[part 1 of 2: packages /MICROSAR/Dem_swc/DataTypes to /MICROSAR/Dem_swc/ComponentTypes]
AUTOSAR XML (schema 00049)
package /MICROSAR/Dem_swc/DataTypes
  26 x impl type:
    Dem_EventIdType: range raw 1..65535, implementation-data-type=uint16
    Dem_RatioIdType: range raw 1..65535, implementation-data-type=uint16
    Dem_DTCStatusMaskType: range raw 0..255, implementation-data-type=uint8
    Dem_OperationCycleIdType: range raw 0..255, implementation-data-type=uint8
    Dem_DTCGroupType: range raw 0..16777215, implementation-data-type=uint32
    Dem_EventStatusType:
      compu {0=DEM_EVENT_STATUS_PASSED, 1=DEM_EVENT_STATUS_FAILED, 2=DEM_EVENT_STATUS_PREPASSED, 3=DEM_EVENT_STATUS_PREFAILED, 4=DEM_EVENT_STATUS_FDC_THRESHOLD_REACHED, 5=DEM_EVENT_STATUS_PASSED_CONDITIONS_NOT_FULFILLED, 6=DEM_EVENT_STATUS_FAILED_CONDITIONS_NOT_FULFILLED, 7=DEM_EVENT_STATUS_PREPASSED_CONDITIONS_NOT_FULFILLED, 8=DEM_EVENT_STATUS_PREFAILED_CONDITIONS_NOT_FULFILLED}
      range raw 0..255
      implementation-data-type=uint8
    Dem_InitMonitorReasonType: compu {1=DEM_INIT_MONITOR_CLEAR, 2=DEM_INIT_MONITOR_RESTART, 3=DEM_INIT_MONITOR_REENABLED, 4=DEM_INIT_MONITOR_STORAGE_REENABLED}, range raw 1..4, implementation-data-type=uint8
    Dem_DTCFormatType: compu {0=DEM_DTC_FORMAT_OBD, 1=DEM_DTC_FORMAT_UDS, 2=DEM_DTC_FORMAT_J1939}, range raw 0..2, implementation-data-type=uint8
    Dem_OperationCycleStateType: compu {0=DEM_CYCLE_STATE_START, 1=DEM_CYCLE_STATE_END}, range raw 0..1, implementation-data-type=uint8
    Dem_IndicatorStatusType: compu {0=DEM_INDICATOR_OFF, 1=DEM_INDICATOR_CONTINUOUS, 2=DEM_INDICATOR_BLINKING, 3=DEM_INDICATOR_BLINK_CONT, 4=DEM_INDICATOR_SLOW_FLASH, 5=DEM_INDICATOR_FAST_FLASH, 6=DEM_INDICATOR_ON_DEMAND, 7=DEM_INDICATOR_SHORT}, range raw 0..7, implementation-data-type=uint8
    Dem_DTCKindType: compu {1=DEM_DTC_KIND_ALL_DTCS, 2=DEM_DTC_KIND_EMISSION_REL_DTCS}, range raw 0..255, implementation-data-type=uint8
    Dem_IumprDenomCondIdType: compu {1=DEM_IUMPR_GENERAL_DENOMINATOR, 2=DEM_IUMPR_DEN_COND_COLDSTART, 3=DEM_IUMPR_DEN_COND_EVAP, 4=DEM_IUMPR_DEN_COND_500MI, 5=DEM_IUMPR_GENERAL_INDIVIDUAL_DENOMINATOR, 6=DEM_IUMPR_GENERAL_OBDCOND, 7=DEM_IUMPR_DEN_COND_INDEPENDENT}, range raw 0..255, implementation-data-type=uint8
    Dem_IumprDenomCondStatusType: compu {0=DEM_IUMPR_DEN_STATUS_NOT_REACHED, 1=DEM_IUMPR_DEN_STATUS_REACHED, 2=DEM_IUMPR_DEN_STATUS_INHIBITED}, range raw 0..255, implementation-data-type=uint8
    Dem_DebounceResetStatusType: compu {0=DEM_DEBOUNCE_STATUS_FREEZE, 1=DEM_DEBOUNCE_STATUS_RESET}, range raw 0..255, implementation-data-type=uint8
    Dem_IumprReadinessGroupType:
      compu {0=DEM_IUMPR_BOOSTPRS, 1=DEM_IUMPR_CAT1, 2=DEM_IUMPR_CAT2, 3=DEM_IUMPR_EGR, 4=DEM_IUMPR_EGSENSOR, 5=DEM_IUMPR_EVAP, 6=DEM_IUMPR_NMHCCAT, 7=DEM_IUMPR_NOXADSORB, 8=DEM_IUMPR_NOXCAT, 9=DEM_IUMPR_OXS1, 10=DEM_IUMPR_OXS2, 11=DEM_IUMPR_PMFILTER, 12=DEM_IUMPR_PRIVATE, 13=DEM_IUMPR_SAIR, 14=DEM_IUMPR_SECOXS1, 15=DEM_IUMPR_SECOXS2, 16=DEM_IUMPR_FLSYS, 17=DEM_IUMPR_AFRI1, 18=DEM_IUMPR_AFRI2, 19=DEM_IUMPR_PF1, 20=DEM_IUMPR_PF2, 255=DEM_IUMPR_ALLGROUPS}
      range raw 0..255
      implementation-data-type=uint8
    Dem_DTRControlType: compu {0=DEM_DTR_CTL_NORMAL, 1=DEM_DTR_CTL_NO_MAX, 2=DEM_DTR_CTL_NO_MIN, 3=DEM_DTR_CTL_RESET, 4=DEM_DTR_CTL_INVISIBLE}, range raw 0..255, implementation-data-type=uint8
    Dem_DebouncingStateType:
      compu {mask 1: 1=DEM_TEMPORARILY_DEFECTIVE (Bit 0: Temporarily Defective (corresponds to 0 < FDC < 127)), mask 2: 2=DEM_FINALLY_DEFECTIVE (Bit 1: Finally Defective (corresponds to FDC = 127)), mask 4: 4=DEM_TEMPORARILY_HEALED (Bit 2: Temporarily healed (corresponds to -128 < FDC < 0)), mask 8: 8=DEM_TEST_COMPLETE (Bit 3: Test complete (corresponds to FDC = -128 or FDC = 127)), mask 16: 16=DEM_DTR_UPDATE (Bit 4: DTR Update (= Test complete && Debouncing complete && enable conditions / storage conditions fulfilled))}
      range raw 0..255
      implementation-data-type=uint8
    Dem_DTCSeverityType:
      compu {mask 255: 0=DEM_SEVERITY_NO_SEVERITY (DTC_NO_SEVERITY) (No severity information available), mask 31: 1=DEM_SEVERITY_WWHOBD_CLASS_NO_CLASS (DTC_CLASS) (No class information), mask 31: 2=DEM_SEVERITY_WWHOBD_CLASS_A (DTC_CLASS) (WWH-OBD Class A), mask 31: 4=DEM_SEVERITY_WWHOBD_CLASS_B1 (DTC_CLASS) (WWH-OBD Class B1), mask 31: 8=DEM_SEVERITY_WWHOBD_CLASS_B2 (DTC_CLASS) (WWH-OBD Class B2), mask 31: 16=DEM_SEVERITY_WWHOBD_CLASS_C (DTC_CLASS) (WWH-OBD Class C), mask 224: 32=DEM_SEVERITY_MAINTENANCE_ONLY (DTC_SEVERITY) (Maintenance required), mask 224: 64=DEM_SEVERITY_CHECK_AT_NEXT_HALT (DTC_SEVERITY) (Check at next halt), mask 224: 128=DEM_SEVERITY_CHECK_IMMEDIATELY (DTC_SEVERITY) (Check immediately)}
      range raw 0..255
      implementation-data-type=uint8
    Dem_UdsStatusByteType:
      compu {mask 1: 1=DEM_UDS_STATUS_TF (bit 0: TestFailed), mask 2: 2=DEM_UDS_STATUS_TFTOC (bit 1: TestFailedThisOperationCycle), mask 4: 4=DEM_UDS_STATUS_PDTC (bit 2: PendingDTC), mask 8: 8=DEM_UDS_STATUS_CDTC (bit 3: ConfirmedDTC), mask 16: 16=DEM_UDS_STATUS_TNCSLC (bit 4: TestNotCompletedSinceLastClear), mask 32: 32=DEM_UDS_STATUS_TFSLC (bit 5: TestFailedSinceLastClear), mask 64: 64=DEM_UDS_STATUS_TNCTOC (bit 6: TestNotCompletedThisOperationCycle), mask 128: 128=DEM_UDS_STATUS_WIR (bit 7: WarningIndicatorRequested)}
      range raw 0..255
      implementation-data-type=uint8
    Dem_MonitorStatusType: compu {mask 1: 1=DEM_MONITOR_STATUS_TF (bit 0: TestFailed), mask 2: 2=DEM_MONITOR_STATUS_TNCTOC (bit 1: TestNotCompletedThisOperationCycle)}, range raw 0..255, implementation-data-type=uint8
    Dem_DTCOriginType: compu {1=DEM_DTC_ORIGIN_PRIMARY_MEMORY, 2=DEM_DTC_ORIGIN_MIRROR_MEMORY, 3=DEM_DTC_ORIGIN_PERMANENT_MEMORY, 4=DEM_DTC_ORIGIN_OBD_RELEVANT_MEMORY, 256=DEM_DTC_ORIGIN_SECONDARY_MEMORY}, range raw 1..511, implementation-data-type=uint16
    DataPrimitiveType_uint32: implementation-data-type=uint32
    DataPrimitiveType_uint16: implementation-data-type=uint16
    DataPrimitiveType_uint8: implementation-data-type=uint8
    DataArrayType_uint8_2: category=ARRAY, sw-calibration-access=READ-ONLY
      element DataArrayType_uint8_2Element: array-size=2, array-size-semantics=FIXED-SIZE, implementation-data-type=uint8
    Dem_MaxDataValueType: category=ARRAY, sw-calibration-access=READ-ONLY
      element Dem_MaxDataValueTypeElement: array-size=5, array-size-semantics=FIXED-SIZE, implementation-data-type=uint8
package /MICROSAR/Dem_swc/Interfaces
  19 x client server interface, all with is-service=true, service-kind=DIAGNOSTIC-EVENT-MANAGER:
    DemServices
      operation GetPostRunRequested: possible-error=DemServices/E_NOT_OK
        arg IsRequested: type=boolean, direction=OUT
      operation GetDTCStatusAvailabilityMask: possible-error=DemServices/E_NOT_OK
        arg ClientId: type=uint8, direction=IN
        arg DTCStatusMask: type=uint8, direction=OUT
      error E_NOT_OK: error-code=1
    DemSc
      operation GetCurrentOdometer: possible-error=DemSc/E_NOT_OK
        arg Odometer: type=uint32, direction=OUT
      operation GetExternalTesterStatus: possible-error=DemSc/E_NOT_OK
        arg TesterPresent: type=boolean, direction=OUT
      error E_NOT_OK: error-code=1
    ClearDTC
      operation ClearDTC: possible-error=[ClearDTC/E_NOT_OK, DEM_CLEAR_FAILED, ClearDTC/DEM_PENDING, DEM_CLEAR_BUSY, DEM_CLEAR_MEMORY_ERROR, ClearDTC/DEM_WRONG_DTC, ClearDTC/DEM_WRONG_DTCORIGIN]
      operation SelectDTC: possible-error=[ClearDTC/E_OK, ClearDTC/E_NOT_OK]
        arg DTC: type=uint32, direction=IN
        arg DTCFormat: type=Dem_DTCFormatType, direction=IN
        arg DTCOrigin: type=Dem_DTCOriginType, direction=IN
      8 x error:
        E_OK: error-code=0
        E_NOT_OK: error-code=1
        DEM_CLEAR_FAILED: error-code=7
        DEM_PENDING: error-code=4
        DEM_CLEAR_BUSY: error-code=5
        DEM_CLEAR_MEMORY_ERROR: error-code=6
        DEM_WRONG_DTC: error-code=8
        DEM_WRONG_DTCORIGIN: error-code=9
    EnableCondition
      operation SetEnableCondition: possible-error=EnableCondition/E_NOT_OK
        arg ConditionFulfilled: type=boolean, direction=IN
      error E_NOT_OK: error-code=1
    IndicatorStatus
      operation GetIndicatorStatus: possible-error=IndicatorStatus/E_NOT_OK
        arg IndicatorStatus: type=Dem_IndicatorStatusType, direction=OUT
      error E_NOT_OK: error-code=1
    EvMemOverflowIndication
      operation GetEventMemoryOverflow: possible-error=EvMemOverflowIndication/E_NOT_OK
        arg OverflowIndication: type=boolean, direction=OUT
      operation GetNumberOfEventMemoryEntries: possible-error=EvMemOverflowIndication/E_NOT_OK
        arg NumberOfEventMemoryEntries: type=uint8, direction=OUT
      error E_NOT_OK: error-code=1
    GeneralDiagnosticInfo
      11 x operation:
        GetEventUdsStatus: possible-error=GeneralDiagnosticInfo/E_NOT_OK
          arg EventId: type=Dem_EventIdType, direction=IN
          arg UDSStatusByte: type=Dem_UdsStatusByteType, direction=OUT
        GetEventStatus: possible-error=GeneralDiagnosticInfo/E_NOT_OK
          arg EventId: type=Dem_EventIdType, direction=IN
          arg UDSStatusByte: type=Dem_UdsStatusByteType, direction=OUT
        GetEventFailed: possible-error=GeneralDiagnosticInfo/E_NOT_OK
          arg EventId: type=Dem_EventIdType, direction=IN
          arg EventFailed: type=boolean, direction=OUT
        GetEventTested: possible-error=GeneralDiagnosticInfo/E_NOT_OK
          arg EventId: type=Dem_EventIdType, direction=IN
          arg EventTested: type=boolean, direction=OUT
        GetDTCOfEvent: possible-error=[GeneralDiagnosticInfo/E_NOT_OK, GeneralDiagnosticInfo/DEM_E_NO_DTC_AVAILABLE]
          arg EventId: type=Dem_EventIdType, direction=IN
          arg DTCFormat: type=Dem_DTCFormatType, direction=IN
          arg DTCOfEvent: type=uint32, direction=OUT
        GetFaultDetectionCounter: possible-error=[GeneralDiagnosticInfo/E_NOT_OK, GeneralDiagnosticInfo/DEM_E_NO_FDC_AVAILABLE]
          arg EventId: type=Dem_EventIdType, direction=IN
          arg FaultDetectionCounter: type=sint8, direction=OUT
        GetEventFreezeFrameDataEx: possible-error=[GeneralDiagnosticInfo/E_NOT_OK, GeneralDiagnosticInfo/DEM_BUFFER_TOO_SMALL, GeneralDiagnosticInfo/DEM_NO_SUCH_ELEMENT]
          5 x arg:
            EventId: type=Dem_EventIdType, direction=IN
            RecordNumber: type=uint8, direction=IN
            DataId: type=uint16, direction=IN
            DestBuffer: type=Dem_MaxDataValueType, direction=OUT
            BufSize: type=uint16, direction=INOUT
        GetEventExtendedDataRecordEx: possible-error=[GeneralDiagnosticInfo/E_NOT_OK, GeneralDiagnosticInfo/DEM_BUFFER_TOO_SMALL, GeneralDiagnosticInfo/DEM_NO_SUCH_ELEMENT]
          4 x arg:
            EventId: type=Dem_EventIdType, direction=IN
            RecordNumber: type=uint8, direction=IN
            DestBuffer: type=Dem_MaxDataValueType, direction=OUT
            BufSize: type=uint16, direction=INOUT
        GetEventEnableCondition: possible-error=GeneralDiagnosticInfo/E_NOT_OK
          arg EventId: type=Dem_EventIdType, direction=IN
          arg ConditionFullfilled: type=boolean, direction=OUT
        GetDebouncingOfEvent: possible-error=GeneralDiagnosticInfo/E_NOT_OK
          arg EventId: type=Dem_EventIdType, direction=IN
          arg DebouncingState: type=Dem_DebouncingStateType, direction=OUT
        GetMonitorStatus: possible-error=GeneralDiagnosticInfo/E_NOT_OK
          arg EventId: type=Dem_EventIdType, direction=IN
          arg MonitorStatus: type=Dem_MonitorStatusType, direction=OUT
      5 x error:
        E_NOT_OK: error-code=1
        DEM_E_NO_DTC_AVAILABLE: error-code=10
        DEM_E_NO_FDC_AVAILABLE: error-code=14
        DEM_BUFFER_TOO_SMALL: error-code=21
        DEM_NO_SUCH_ELEMENT: error-code=48
    OperationCycle
      operation GetOperationCycleState: possible-error=[OperationCycle/E_OK, OperationCycle/E_NOT_OK]
        arg CycleState: type=Dem_OperationCycleStateType, direction=OUT
      operation SetOperationCycleState: possible-error=[OperationCycle/E_OK, OperationCycle/E_NOT_OK]
        arg CycleState: type=Dem_OperationCycleStateType, direction=IN
      error E_OK: error-code=0
      error E_NOT_OK: error-code=1
    CallbackDTCStatusChange
      operation DTCStatusChanged: possible-error=CallbackDTCStatusChange/E_NOT_OK
        arg DTC: type=uint32, direction=IN
        arg DTCStatusOld: type=Dem_UdsStatusByteType, direction=IN
        arg DTCStatusNew: type=Dem_UdsStatusByteType, direction=IN
      error E_NOT_OK: error-code=1
    CSDataServices_Data_DID_0x133_Current_Operating_Time
      operation ReadData: possible-error=CSDataServices_Data_DID_0x133_Current_Operating_Time/E_NOT_OK
        arg Data: type=DataPrimitiveType_uint32, direction=OUT
      error E_NOT_OK: error-code=1
    CSDataServices_Data_DID_0x10a_Vehicle_Odometer_in_Low_Resolution
      operation ReadData: possible-error=CSDataServices_Data_DID_0x10a_Vehicle_Odometer_in_Low_Resolution/E_NOT_OK
        arg Data: type=DataPrimitiveType_uint16, direction=OUT
      error E_NOT_OK: error-code=1
    CSDataServices_Data_DID_0x18b_SecOcDataID
      operation ReadData: possible-error=CSDataServices_Data_DID_0x18b_SecOcDataID/E_NOT_OK
        arg Data: type=DataArrayType_uint8_2, direction=OUT
      error E_NOT_OK: error-code=1
    CSDataServices_Data_DID_0x133_Operating_Time_Status
      operation ReadData: possible-error=CSDataServices_Data_DID_0x133_Operating_Time_Status/E_NOT_OK
        arg Data: type=DataPrimitiveType_uint8, direction=OUT
      error E_NOT_OK: error-code=1
    DiagnosticInfo
      11 x operation:
        GetEventUdsStatus: possible-error=DiagnosticInfo/E_NOT_OK
          arg UDSStatusByte: type=Dem_UdsStatusByteType, direction=OUT
        GetEventStatus: possible-error=DiagnosticInfo/E_NOT_OK
          arg UDSStatusByte: type=Dem_UdsStatusByteType, direction=OUT
        GetEventFailed: possible-error=DiagnosticInfo/E_NOT_OK
          arg EventFailed: type=boolean, direction=OUT
        GetEventTested: possible-error=DiagnosticInfo/E_NOT_OK
          arg EventTested: type=boolean, direction=OUT
        GetDTCOfEvent: possible-error=[DiagnosticInfo/E_NOT_OK, DiagnosticInfo/DEM_E_NO_DTC_AVAILABLE]
          arg DTCFormat: type=Dem_DTCFormatType, direction=IN
          arg DTCOfEvent: type=uint32, direction=OUT
        GetFaultDetectionCounter: possible-error=[DiagnosticInfo/E_NOT_OK, DiagnosticInfo/DEM_E_NO_FDC_AVAILABLE]
          arg FaultDetectionCounter: type=sint8, direction=OUT
        GetEventFreezeFrameDataEx: possible-error=[DiagnosticInfo/E_NOT_OK, DiagnosticInfo/DEM_BUFFER_TOO_SMALL, DiagnosticInfo/DEM_NO_SUCH_ELEMENT]
          4 x arg:
            RecordNumber: type=uint8, direction=IN
            DataId: type=uint16, direction=IN
            DestBuffer: type=Dem_MaxDataValueType, direction=OUT
            BufSize: type=uint16, direction=INOUT
        GetEventExtendedDataRecordEx: possible-error=[DiagnosticInfo/E_NOT_OK, DiagnosticInfo/DEM_BUFFER_TOO_SMALL, DiagnosticInfo/DEM_NO_SUCH_ELEMENT]
          arg RecordNumber: type=uint8, direction=IN
          arg DestBuffer: type=Dem_MaxDataValueType, direction=OUT
          arg BufSize: type=uint16, direction=INOUT
        GetEventEnableCondition: possible-error=DiagnosticInfo/E_NOT_OK
          arg ConditionFullfilled: type=boolean, direction=OUT
        GetDebouncingOfEvent: possible-error=DiagnosticInfo/E_NOT_OK
          arg DebouncingState: type=Dem_DebouncingStateType, direction=OUT
        GetMonitorStatus: possible-error=DiagnosticInfo/E_NOT_OK
          arg MonitorStatus: type=Dem_MonitorStatusType, direction=OUT
      5 x error:
        E_NOT_OK: error-code=1
        DEM_E_NO_DTC_AVAILABLE: error-code=10
        DEM_E_NO_FDC_AVAILABLE: error-code=14
        DEM_BUFFER_TOO_SMALL: error-code=21
        DEM_NO_SUCH_ELEMENT: error-code=48
    DiagnosticMonitor
      11 x operation:
        SetEventStatus: possible-error=DiagnosticMonitor/E_NOT_OK
          arg EventStatus: type=Dem_EventStatusType, direction=IN
        ResetEventStatus: possible-error=DiagnosticMonitor/E_NOT_OK
        ResetEventDebounceStatus: possible-error=DiagnosticMonitor/E_NOT_OK
          arg DebounceResetStatus: type=Dem_DebounceResetStatusType, direction=IN
        GetEventUdsStatus: possible-error=DiagnosticMonitor/E_NOT_OK
          arg UDSStatusByte: type=Dem_UdsStatusByteType, direction=OUT
        GetEventStatus: possible-error=DiagnosticMonitor/E_NOT_OK
          arg UDSStatusByte: type=Dem_UdsStatusByteType, direction=OUT
        GetEventFailed: possible-error=DiagnosticMonitor/E_NOT_OK
          arg EventFailed: type=boolean, direction=OUT
        GetEventTested: possible-error=DiagnosticMonitor/E_NOT_OK
          arg EventTested: type=boolean, direction=OUT
        GetDTCOfEvent: possible-error=[DiagnosticMonitor/E_NOT_OK, DiagnosticMonitor/DEM_E_NO_DTC_AVAILABLE]
          arg DTCFormat: type=Dem_DTCFormatType, direction=IN
          arg DTCOfEvent: type=uint32, direction=OUT
        GetFaultDetectionCounter: possible-error=[DiagnosticMonitor/E_NOT_OK, DiagnosticMonitor/DEM_E_NO_FDC_AVAILABLE]
          arg FaultDetectionCounter: type=sint8, direction=OUT
        GetEventFreezeFrameDataEx: possible-error=[DiagnosticMonitor/E_NOT_OK, DiagnosticMonitor/DEM_BUFFER_TOO_SMALL, DiagnosticMonitor/DEM_NO_SUCH_ELEMENT]
          4 x arg:
            RecordNumber: type=uint8, direction=IN
            DataId: type=uint16, direction=IN
            DestBuffer: type=Dem_MaxDataValueType, direction=OUT
            BufSize: type=uint16, direction=INOUT
        GetEventExtendedDataRecordEx: possible-error=[DiagnosticMonitor/E_NOT_OK, DiagnosticMonitor/DEM_BUFFER_TOO_SMALL, DiagnosticMonitor/DEM_NO_SUCH_ELEMENT]
          arg RecordNumber: type=uint8, direction=IN
          arg DestBuffer: type=Dem_MaxDataValueType, direction=OUT
          arg BufSize: type=uint16, direction=INOUT
      5 x error:
        E_NOT_OK: error-code=1
        DEM_E_NO_DTC_AVAILABLE: error-code=10
        DEM_E_NO_FDC_AVAILABLE: error-code=14
        DEM_BUFFER_TOO_SMALL: error-code=21
        DEM_NO_SUCH_ELEMENT: error-code=48
    CallbackInitMonitorForEvent
      operation InitMonitorForEvent: possible-error=CallbackInitMonitorForEvent/E_NOT_OK
        arg InitMonitorReason: type=Dem_InitMonitorReasonType, direction=IN
      error E_NOT_OK: error-code=1
    DTCSuppression
      operation SetDTCSuppression: possible-error=[DTCSuppression/E_NOT_OK, DTCSuppression/DEM_WRONG_DTC, DTCSuppression/DEM_WRONG_DTCORIGIN, DTCSuppression/DEM_PENDING]
        arg SuppressionStatus: type=boolean, direction=IN
      operation GetDTCSuppression: possible-error=[DTCSuppression/E_NOT_OK, DTCSuppression/DEM_WRONG_DTC, DTCSuppression/DEM_WRONG_DTCORIGIN, DTCSuppression/DEM_PENDING]
        arg SuppressionStatus: type=boolean, direction=OUT
      4 x error:
        E_NOT_OK: error-code=1
        DEM_WRONG_DTC: error-code=8
        DEM_WRONG_DTCORIGIN: error-code=9
        DEM_PENDING: error-code=4
    StorageCondition
      operation SetStorageCondition: possible-error=StorageCondition/E_NOT_OK
        arg ConditionFulfilled: type=boolean, direction=IN
      error E_NOT_OK: error-code=1
    CSDataServices_Data_DID_0xfd05_Root_Causes
      operation ReadData: possible-error=CSDataServices_Data_DID_0xfd05_Root_Causes/E_NOT_OK
        arg Data: type=DataPrimitiveType_uint8, direction=OUT
      error E_NOT_OK: error-code=1
package /MICROSAR/Dem_swc/ComponentTypes
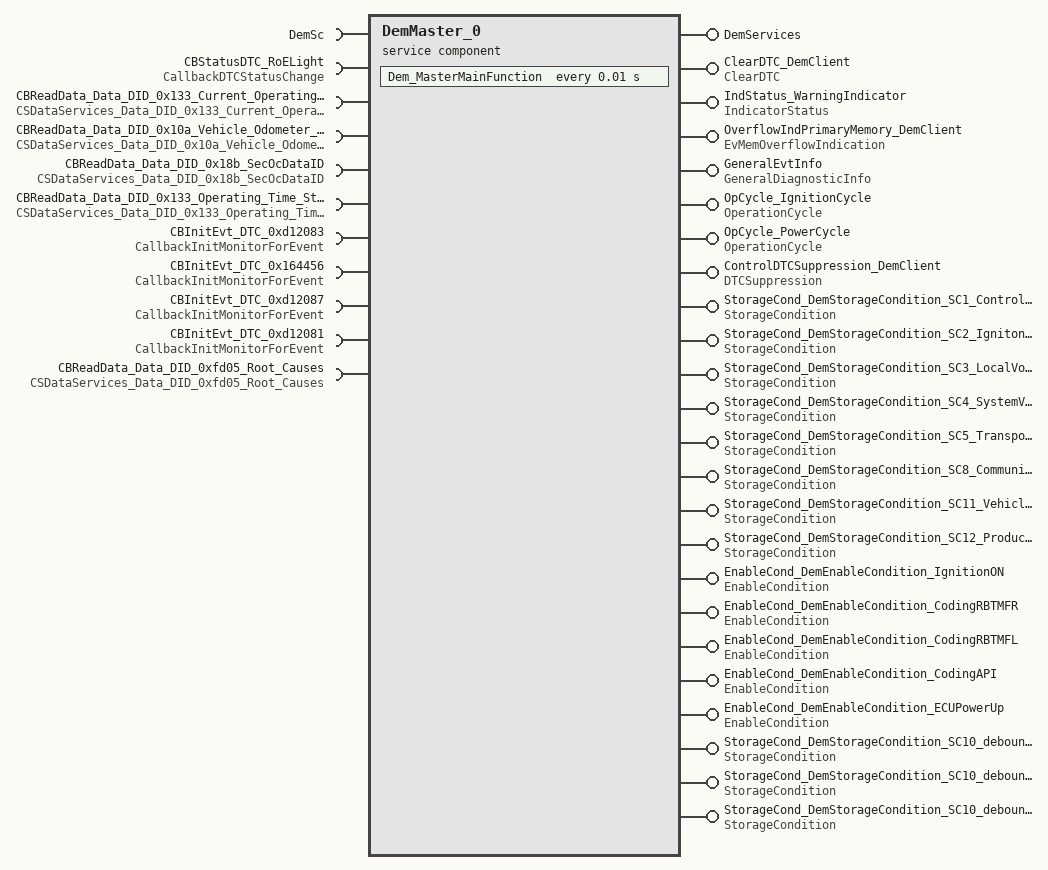
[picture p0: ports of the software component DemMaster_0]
  service sw component type DemMaster_0: category=SERVICE_COMPONENT
    provide port DemServices: provided-interface=DemServices
    require port DemSc: required-interface=DemSc
    6 x provide port:
      ClearDTC_DemClient: provided-interface=ClearDTC
      IndStatus_WarningIndicator: provided-interface=IndicatorStatus
      OverflowIndPrimaryMemory_DemClient: provided-interface=EvMemOverflowIndication
      GeneralEvtInfo: provided-interface=GeneralDiagnosticInfo
      OpCycle_IgnitionCycle: provided-interface=OperationCycle
      OpCycle_PowerCycle: provided-interface=OperationCycle
    9 x require port:
      CBStatusDTC_RoELight: required-interface=CallbackDTCStatusChange
      CBReadData_Data_DID_0x133_Current_Operating_Time: required-interface=CSDataServices_Data_DID_0x133_Current_Operating_Time
      CBReadData_Data_DID_0x10a_Vehicle_Odometer_in_Low_Resolution: required-interface=CSDataServices_Data_DID_0x10a_Vehicle_Odometer_in_Low_Resolution
      CBReadData_Data_DID_0x18b_SecOcDataID: required-interface=CSDataServices_Data_DID_0x18b_SecOcDataID
      CBReadData_Data_DID_0x133_Operating_Time_Status: required-interface=CSDataServices_Data_DID_0x133_Operating_Time_Status
      CBInitEvt_DTC_0xd12083: required-interface=CallbackInitMonitorForEvent
      CBInitEvt_DTC_0x164456: required-interface=CallbackInitMonitorForEvent
      CBInitEvt_DTC_0xd12087: required-interface=CallbackInitMonitorForEvent
      CBInitEvt_DTC_0xd12081: required-interface=CallbackInitMonitorForEvent
    17 x provide port:
      ControlDTCSuppression_DemClient: provided-interface=DTCSuppression
      StorageCond_DemStorageCondition_SC1_ControlDTC: provided-interface=StorageCondition
      StorageCond_DemStorageCondition_SC2_IgnitonStatus: provided-interface=StorageCondition
      StorageCond_DemStorageCondition_SC3_LocalVoltage: provided-interface=StorageCondition
      StorageCond_DemStorageCondition_SC4_SystemVoltage: provided-interface=StorageCondition
      StorageCond_DemStorageCondition_SC5_TransportationMode: provided-interface=StorageCondition
      StorageCond_DemStorageCondition_SC8_CommunicationStatus: provided-interface=StorageCondition
      StorageCond_DemStorageCondition_SC11_VehicleStartup: provided-interface=StorageCondition
      StorageCond_DemStorageCondition_SC12_ProductionMode: provided-interface=StorageCondition
      EnableCond_DemEnableCondition_IgnitionON: provided-interface=EnableCondition
      EnableCond_DemEnableCondition_CodingRBTMFR: provided-interface=EnableCondition
      EnableCond_DemEnableCondition_CodingRBTMFL: provided-interface=EnableCondition
      EnableCond_DemEnableCondition_CodingAPI: provided-interface=EnableCondition
      EnableCond_DemEnableCondition_ECUPowerUp: provided-interface=EnableCondition
      StorageCond_DemStorageCondition_SC10_debounceTimerPD: provided-interface=StorageCondition
      StorageCond_DemStorageCondition_SC10_debounceTimerNC: provided-interface=StorageCondition
      StorageCond_DemStorageCondition_SC10_debounceTimerNC15: provided-interface=StorageCondition
    require port CBReadData_Data_DID_0xfd05_Root_Causes: required-interface=CSDataServices_Data_DID_0xfd05_Root_Causes
    behavior DemMaster_0InternalBehavior: handle-termination-and-restart=NO-SUPPORT, included-data-type-set=data-type=[Dem_EventIdType, Dem_RatioIdType, Dem_EventStatusType, Dem_UdsStatusByteType, Dem_DTCFormatType, Dem_InitMonitorReasonType, Dem_OperationCycleStateType, Dem_DTCStatusMaskType, Dem_IndicatorStatusType, Dem_MaxDataValueType, Dem_DTCKindType, Dem_DTCGroupType, Dem_IumprDenomCondIdType, Dem_IumprDenomCondStatusType, Dem_DebounceResetStatusType, Dem_DebouncingStateType, Dem_IumprReadinessGroupType, Dem_DTRControlType, Dem_DTCSeverityType, Dem_MonitorStatusType]
      timing event Timer_Dem_MasterMainFunction: start-on-event=Dem_MasterMainFunction, period=0.01
      40 x operation invoked event:
        OpEventPostRunRequested_GetPostRunRequested_DemServices: start-on-event=PostRunRequested, operation=DemServices.GetPostRunRequested
        OpEventGetDTCStatusAvailabilityMask_GetDTCStatusAvailabilityMask_DemServices: start-on-event=GetDTCStatusAvailabilityMask, operation=DemServices.GetDTCStatusAvailabilityMask
        OpEventClearDTC_ClearDTC_ClearDTC_DemClient: start-on-event=ClearDTC, operation=ClearDTC_DemClient.ClearDTC
        OpEventSelectDTC_SelectDTC_ClearDTC_DemClient: start-on-event=SelectDTC, operation=ClearDTC_DemClient.SelectDTC
        OpEventGetIndicatorStatus_GetIndicatorStatus_IndStatus_WarningIndicator: start-on-event=GetIndicatorStatus, operation=IndStatus_WarningIndicator.GetIndicatorStatus
        OpEventGetEventMemoryOverflow_GetEventMemoryOverflow_OverflowIndPrimaryMemory_DemClient: start-on-event=GetEventMemoryOverflow, operation=OverflowIndPrimaryMemory_DemClient.GetEventMemoryOverflow
        OpEventGetNumberOfEventMemoryEntries_GetNumberOfEventMemoryEntries_OverflowIndPrimaryMemory_DemClient: start-on-event=GetNumberOfEventMemoryEntries, operation=OverflowIndPrimaryMemory_DemClient.GetNumberOfEventMemoryEntries
        OpEventGetEventUdsStatus_GetEventUdsStatus_GeneralEvtInfo: start-on-event=DemMaster_0InternalBehavior/GetEventUdsStatus, operation=GeneralEvtInfo.GetEventUdsStatus
        OpEventGetEventStatus_GetEventStatus_GeneralEvtInfo: start-on-event=DemMaster_0InternalBehavior/GetEventStatus, operation=GeneralEvtInfo.GetEventStatus
        OpEventGetEventFailed_GetEventFailed_GeneralEvtInfo: start-on-event=DemMaster_0InternalBehavior/GetEventFailed, operation=GeneralEvtInfo.GetEventFailed
        OpEventGetEventTested_GetEventTested_GeneralEvtInfo: start-on-event=DemMaster_0InternalBehavior/GetEventTested, operation=GeneralEvtInfo.GetEventTested
        OpEventGetDTCOfEvent_GetDTCOfEvent_GeneralEvtInfo: start-on-event=DemMaster_0InternalBehavior/GetDTCOfEvent, operation=GeneralEvtInfo.GetDTCOfEvent
        OpEventGetFaultDetectionCounter_GetFaultDetectionCounter_GeneralEvtInfo: start-on-event=DemMaster_0InternalBehavior/GetFaultDetectionCounter, operation=GeneralEvtInfo.GetFaultDetectionCounter
        OpEventGetEventFreezeFrameDataEx_GetEventFreezeFrameDataEx_GeneralEvtInfo: start-on-event=DemMaster_0InternalBehavior/GetEventFreezeFrameDataEx, operation=GeneralEvtInfo.GetEventFreezeFrameDataEx
        OpEventGetEventExtendedDataRecordEx_GetEventExtendedDataRecordEx_GeneralEvtInfo: start-on-event=DemMaster_0InternalBehavior/GetEventExtendedDataRecordEx, operation=GeneralEvtInfo.GetEventExtendedDataRecordEx
        OpEventGetEventEnableCondition_GetEventEnableCondition_GeneralEvtInfo: start-on-event=DemMaster_0InternalBehavior/GetEventEnableCondition, operation=GeneralEvtInfo.GetEventEnableCondition
        OpEventGetDebouncingOfEvent_GetDebouncingOfEvent_GeneralEvtInfo: start-on-event=DemMaster_0InternalBehavior/GetDebouncingOfEvent, operation=GeneralEvtInfo.GetDebouncingOfEvent
        OpEventGetMonitorStatus_GetMonitorStatus_GeneralEvtInfo: start-on-event=DemMaster_0InternalBehavior/GetMonitorStatus, operation=GeneralEvtInfo.GetMonitorStatus
        OpEventGetOperationCycleState_GetOperationCycleState_OpCycle_IgnitionCycle: start-on-event=GetOperationCycleState, operation=OpCycle_IgnitionCycle.GetOperationCycleState
        OpEventGetOperationCycleState_GetOperationCycleState_OpCycle_PowerCycle: start-on-event=GetOperationCycleState, operation=OpCycle_PowerCycle.GetOperationCycleState
        OpEventSetOperationCycleState_SetOperationCycleState_OpCycle_IgnitionCycle: start-on-event=SetOperationCycleState, operation=OpCycle_IgnitionCycle.SetOperationCycleState
        OpEventSetOperationCycleState_SetOperationCycleState_OpCycle_PowerCycle: start-on-event=SetOperationCycleState, operation=OpCycle_PowerCycle.SetOperationCycleState
        OpEventSetDTCSuppression_SetDTCSuppression_ControlDTCSuppression_DemClient: start-on-event=SetDTCSuppression, operation=ControlDTCSuppression_DemClient.SetDTCSuppression
        OpEventGetDTCSuppression_GetDTCSuppression_ControlDTCSuppression_DemClient: start-on-event=GetDTCSuppression, operation=ControlDTCSuppression_DemClient.GetDTCSuppression
        OpEventSetStorageCondition_SetStorageCondition_StorageCond_DemStorageCondition_SC1_ControlDTC: start-on-event=SetStorageCondition, operation=StorageCond_DemStorageCondition_SC1_ControlDTC.SetStorageCondition
        OpEventSetStorageCondition_SetStorageCondition_StorageCond_DemStorageCondition_SC2_IgnitonStatus: start-on-event=SetStorageCondition, operation=StorageCond_DemStorageCondition_SC2_IgnitonStatus.SetStorageCondition
        OpEventSetStorageCondition_SetStorageCondition_StorageCond_DemStorageCondition_SC3_LocalVoltage: start-on-event=SetStorageCondition, operation=StorageCond_DemStorageCondition_SC3_LocalVoltage.SetStorageCondition
        OpEventSetStorageCondition_SetStorageCondition_StorageCond_DemStorageCondition_SC4_SystemVoltage: start-on-event=SetStorageCondition, operation=StorageCond_DemStorageCondition_SC4_SystemVoltage.SetStorageCondition
        OpEventSetStorageCondition_SetStorageCondition_StorageCond_DemStorageCondition_SC5_TransportationMode: start-on-event=SetStorageCondition, operation=StorageCond_DemStorageCondition_SC5_TransportationMode.SetStorageCondition
        OpEventSetStorageCondition_SetStorageCondition_StorageCond_DemStorageCondition_SC8_CommunicationStatus: start-on-event=SetStorageCondition, operation=StorageCond_DemStorageCondition_SC8_CommunicationStatus.SetStorageCondition
        OpEventSetStorageCondition_SetStorageCondition_StorageCond_DemStorageCondition_SC11_VehicleStartup: start-on-event=SetStorageCondition, operation=StorageCond_DemStorageCondition_SC11_VehicleStartup.SetStorageCondition
        OpEventSetStorageCondition_SetStorageCondition_StorageCond_DemStorageCondition_SC12_ProductionMode: start-on-event=SetStorageCondition, operation=StorageCond_DemStorageCondition_SC12_ProductionMode.SetStorageCondition
        OpEventSetEnableCondition_SetEnableCondition_EnableCond_DemEnableCondition_IgnitionON: start-on-event=SetEnableCondition, operation=EnableCond_DemEnableCondition_IgnitionON.SetEnableCondition
        OpEventSetEnableCondition_SetEnableCondition_EnableCond_DemEnableCondition_CodingRBTMFR: start-on-event=SetEnableCondition, operation=EnableCond_DemEnableCondition_CodingRBTMFR.SetEnableCondition
        OpEventSetEnableCondition_SetEnableCondition_EnableCond_DemEnableCondition_CodingRBTMFL: start-on-event=SetEnableCondition, operation=EnableCond_DemEnableCondition_CodingRBTMFL.SetEnableCondition
        OpEventSetEnableCondition_SetEnableCondition_EnableCond_DemEnableCondition_CodingAPI: start-on-event=SetEnableCondition, operation=EnableCond_DemEnableCondition_CodingAPI.SetEnableCondition
        OpEventSetEnableCondition_SetEnableCondition_EnableCond_DemEnableCondition_ECUPowerUp: start-on-event=SetEnableCondition, operation=EnableCond_DemEnableCondition_ECUPowerUp.SetEnableCondition
        OpEventSetStorageCondition_SetStorageCondition_StorageCond_DemStorageCondition_SC10_debounceTimerPD: start-on-event=SetStorageCondition, operation=StorageCond_DemStorageCondition_SC10_debounceTimerPD.SetStorageCondition
        OpEventSetStorageCondition_SetStorageCondition_StorageCond_DemStorageCondition_SC10_debounceTimerNC: start-on-event=SetStorageCondition, operation=StorageCond_DemStorageCondition_SC10_debounceTimerNC.SetStorageCondition
        OpEventSetStorageCondition_SetStorageCondition_StorageCond_DemStorageCondition_SC10_debounceTimerNC15: start-on-event=SetStorageCondition, operation=StorageCond_DemStorageCondition_SC10_debounceTimerNC15.SetStorageCondition
      port-api-options:
        enable-take-address=true, indirect-api=false, port=DemServices
        enable-take-address=true, indirect-api=false, port=DemSc
        {enable-take-address=true, indirect-api=false, port-defined-argument-value{value=0, value-type=uint8}, port=ClearDTC_DemClient}
        {enable-take-address=true, indirect-api=false, port-defined-argument-value{value=0, value-type=uint8}, port=IndStatus_WarningIndicator}
        enable-take-address=true, indirect-api=false, port=DemMaster_0/GeneralEvtInfo
        {enable-take-address=true, indirect-api=false, port-defined-argument-value{value=0, value-type=uint8}, port=OpCycle_IgnitionCycle}
        {enable-take-address=true, indirect-api=false, port-defined-argument-value{value=1, value-type=uint8}, port=OpCycle_PowerCycle}
        enable-take-address=true, indirect-api=false, port=CBStatusDTC_RoELight
        enable-take-address=true, indirect-api=false, port=DemMaster_0/CBReadData_Data_DID_0x133_Current_Operating_Time
        enable-take-address=true, indirect-api=false, port=DemMaster_0/CBReadData_Data_DID_0x10a_Vehicle_Odometer_in_Low_Resolution
        enable-take-address=true, indirect-api=false, port=DemMaster_0/CBReadData_Data_DID_0x18b_SecOcDataID
        enable-take-address=true, indirect-api=false, port=DemMaster_0/CBReadData_Data_DID_0x133_Operating_Time_Status
        enable-take-address=true, indirect-api=false, port=CBInitEvt_DTC_0xd12083
        enable-take-address=true, indirect-api=false, port=CBInitEvt_DTC_0x164456
        enable-take-address=true, indirect-api=false, port=CBInitEvt_DTC_0xd12087
        enable-take-address=true, indirect-api=false, port=CBInitEvt_DTC_0xd12081
        {enable-take-address=true, indirect-api=false, port-defined-argument-value{value=0, value-type=uint8}, port=ControlDTCSuppression_DemClient}
        {enable-take-address=true, indirect-api=false, port-arg-values=[{value=0, value-type=uint8}, {value=1, value-type=Dem_DTCOriginType}], port=OverflowIndPrimaryMemory_DemClient}
        {enable-take-address=true, indirect-api=false, port-defined-argument-value{value=5, value-type=uint8}, port=EnableCond_DemEnableCondition_IgnitionON}
        {enable-take-address=true, indirect-api=false, port-defined-argument-value{value=4, value-type=uint8}, port=EnableCond_DemEnableCondition_CodingRBTMFR}
        {enable-take-address=true, indirect-api=false, port-defined-argument-value{value=3, value-type=uint8}, port=EnableCond_DemEnableCondition_CodingRBTMFL}
        {enable-take-address=true, indirect-api=false, port-defined-argument-value{value=2, value-type=uint8}, port=EnableCond_DemEnableCondition_CodingAPI}
        {enable-take-address=true, indirect-api=false, port-defined-argument-value{value=1, value-type=uint8}, port=EnableCond_DemEnableCondition_ECUPowerUp}
        {enable-take-address=true, indirect-api=false, port-defined-argument-value{value=0, value-type=uint8}, port=StorageCond_DemStorageCondition_SC1_ControlDTC}
        {enable-take-address=true, indirect-api=false, port-defined-argument-value{value=1, value-type=uint8}, port=StorageCond_DemStorageCondition_SC2_IgnitonStatus}
        {enable-take-address=true, indirect-api=false, port-defined-argument-value{value=2, value-type=uint8}, port=StorageCond_DemStorageCondition_SC3_LocalVoltage}
        {enable-take-address=true, indirect-api=false, port-defined-argument-value{value=3, value-type=uint8}, port=StorageCond_DemStorageCondition_SC4_SystemVoltage}
        {enable-take-address=true, indirect-api=false, port-defined-argument-value{value=4, value-type=uint8}, port=StorageCond_DemStorageCondition_SC5_TransportationMode}
        {enable-take-address=true, indirect-api=false, port-defined-argument-value{value=5, value-type=uint8}, port=StorageCond_DemStorageCondition_SC8_CommunicationStatus}
        {enable-take-address=true, indirect-api=false, port-defined-argument-value{value=6, value-type=uint8}, port=StorageCond_DemStorageCondition_SC10_debounceTimerPD}
        {enable-take-address=true, indirect-api=false, port-defined-argument-value{value=9, value-type=uint8}, port=StorageCond_DemStorageCondition_SC11_VehicleStartup}
        {enable-take-address=true, indirect-api=false, port-defined-argument-value{value=10, value-type=uint8}, port=StorageCond_DemStorageCondition_SC12_ProductionMode}
        {enable-take-address=true, indirect-api=false, port-defined-argument-value{value=7, value-type=uint8}, port=StorageCond_DemStorageCondition_SC10_debounceTimerNC}
        {enable-take-address=true, indirect-api=false, port-defined-argument-value{value=8, value-type=uint8}, port=StorageCond_DemStorageCondition_SC10_debounceTimerNC15}
        enable-take-address=true, indirect-api=false, port=DemMaster_0/CBReadData_Data_DID_0xfd05_Root_Causes
      25 x runnable:
        Dem_MasterMainFunction
          12 x sync call, all with timeout=0:
            OpServerCallDem_MasterMainFunction_GetCurrentOdometer_DemSc: operation=DemSc.GetCurrentOdometer
            OpServerCallDem_MasterMainFunction_GetExternalTesterStatus_DemSc: operation=DemSc.GetExternalTesterStatus
            OpServerCallDem_MasterMainFunction_DTCStatusChanged_CBStatusDTC_RoELight: operation=CBStatusDTC_RoELight.DTCStatusChanged
            OpServerCallDem_MasterMainFunction_ReadData_CBReadData_Data_DID_0x133_Current_Operating_Time: operation=CBReadData_Data_DID_0x133_Current_Operating_Time.ReadData
            OpServerCallDem_MasterMainFunction_ReadData_CBReadData_Data_DID_0x10a_Vehicle_Odometer_in_Low_Resolution: operation=CBReadData_Data_DID_0x10a_Vehicle_Odometer_in_Low_Resolution.ReadData
            OpServerCallDem_MasterMainFunction_ReadData_CBReadData_Data_DID_0x18b_SecOcDataID: operation=CBReadData_Data_DID_0x18b_SecOcDataID.ReadData
            OpServerCallDem_MasterMainFunction_ReadData_CBReadData_Data_DID_0x133_Operating_Time_Status: operation=CBReadData_Data_DID_0x133_Operating_Time_Status.ReadData
            OpServerCallDem_MasterMainFunction_InitMonitorForEvent_CBInitEvt_DTC_0xd12083: operation=CBInitEvt_DTC_0xd12083.InitMonitorForEvent
            OpServerCallDem_MasterMainFunction_InitMonitorForEvent_CBInitEvt_DTC_0x164456: operation=CBInitEvt_DTC_0x164456.InitMonitorForEvent
            OpServerCallDem_MasterMainFunction_InitMonitorForEvent_CBInitEvt_DTC_0xd12087: operation=CBInitEvt_DTC_0xd12087.InitMonitorForEvent
            OpServerCallDem_MasterMainFunction_InitMonitorForEvent_CBInitEvt_DTC_0xd12081: operation=CBInitEvt_DTC_0xd12081.InitMonitorForEvent
            OpServerCallDem_MasterMainFunction_ReadData_CBReadData_Data_DID_0xfd05_Root_Causes: operation=CBReadData_Data_DID_0xfd05_Root_Causes.ReadData
        PostRunRequested: can-be-invoked-concurrently=true, symbol=Dem_PostRunRequested
        GetDTCStatusAvailabilityMask: can-be-invoked-concurrently=true, symbol=Dem_GetDTCStatusAvailabilityMask
        ClearDTC: can-be-invoked-concurrently=true, symbol=Dem_ClearDTC
        SelectDTC: can-be-invoked-concurrently=true, symbol=Dem_SelectDTC
        SetEnableCondition: can-be-invoked-concurrently=true, symbol=Dem_SetEnableCondition
        GetIndicatorStatus: can-be-invoked-concurrently=true, symbol=Dem_GetIndicatorStatus
        GetEventMemoryOverflow: can-be-invoked-concurrently=true, symbol=Dem_GetEventMemoryOverflow
        GetNumberOfEventMemoryEntries: can-be-invoked-concurrently=true, symbol=Dem_GetNumberOfEventMemoryEntries
        GetEventUdsStatus: can-be-invoked-concurrently=true, symbol=Dem_GetEventUdsStatus
        GetEventStatus: can-be-invoked-concurrently=true, symbol=Dem_GetEventUdsStatus
        GetEventFailed: can-be-invoked-concurrently=true, symbol=Dem_GetEventFailed
        GetEventTested: can-be-invoked-concurrently=true, symbol=Dem_GetEventTested
        GetDTCOfEvent: can-be-invoked-concurrently=true, symbol=Dem_GetDTCOfEvent
        GetFaultDetectionCounter: can-be-invoked-concurrently=true, symbol=Dem_GetFaultDetectionCounter
        GetEventFreezeFrameDataEx: can-be-invoked-concurrently=true, symbol=Dem_GetEventFreezeFrameDataEx
        GetEventExtendedDataRecordEx: can-be-invoked-concurrently=true, symbol=Dem_GetEventExtendedDataRecordEx
        GetEventEnableCondition: can-be-invoked-concurrently=true, symbol=Dem_GetEventEnableCondition
        GetDebouncingOfEvent: can-be-invoked-concurrently=true, symbol=Dem_GetDebouncingOfEvent
        GetMonitorStatus: can-be-invoked-concurrently=true, symbol=Dem_GetMonitorStatus
        GetOperationCycleState: can-be-invoked-concurrently=true, symbol=Dem_GetOperationCycleState
        SetOperationCycleState: can-be-invoked-concurrently=true, symbol=Dem_SetOperationCycleState
        SetDTCSuppression: can-be-invoked-concurrently=true, symbol=Dem_SetDTCSuppression
        GetDTCSuppression: can-be-invoked-concurrently=true, symbol=Dem_GetDTCSuppression
        SetStorageCondition: can-be-invoked-concurrently=true, symbol=Dem_SetStorageCondition
  swc implementation DemMaster_0Implementation: programming-language=C, behavior=DemMaster_0InternalBehavior
